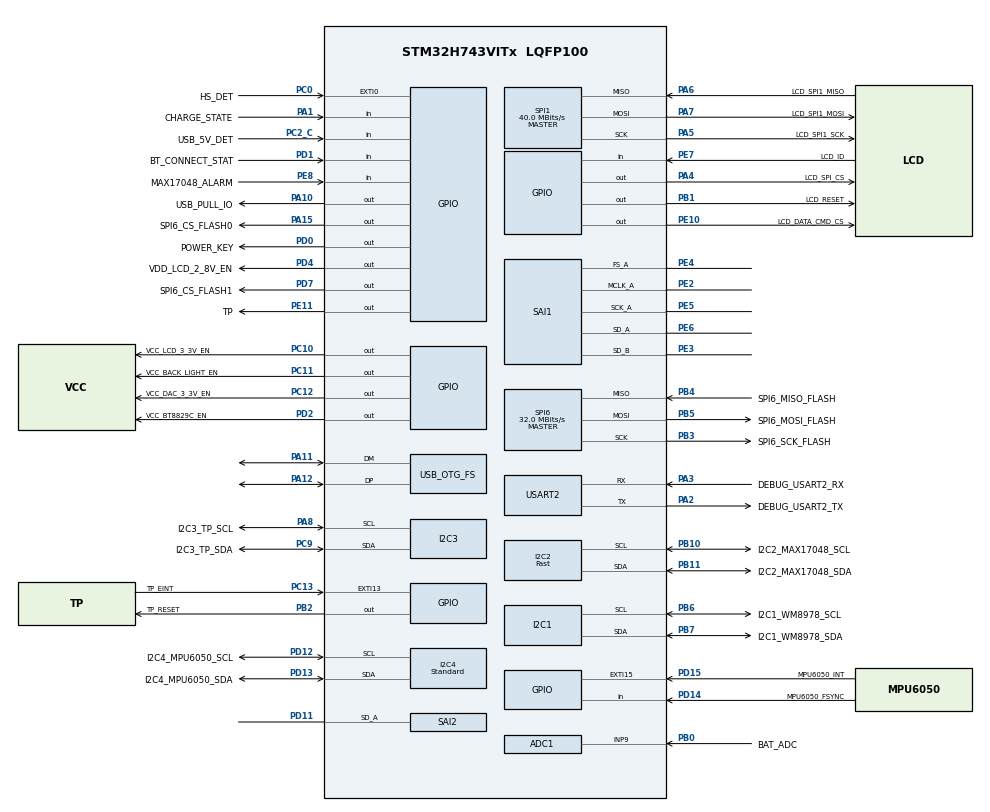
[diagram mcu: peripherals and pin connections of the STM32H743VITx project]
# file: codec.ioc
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ADC1.Channel-5\#ChannelRegularConversion=ADC_CHANNEL_9
ADC1.LowPowerAutoWait=ENABLE
ADC1.NbrOfConversionFlag=1
ADC1.OffsetNumber-5\#ChannelRegularConversion=ADC_OFFSET_NONE
ADC1.OffsetSignedSaturation-5\#ChannelRegularConversion=DISABLE
ADC1.Rank-5\#ChannelRegularConversion=1
ADC1.SamplingTime-5\#ChannelRegularConversion=ADC_SAMPLETIME_1CYCLE_5
ADC1.master=1
Bdma.I2C4_RX.0.Direction=DMA_PERIPH_TO_MEMORY
Bdma.I2C4_RX.0.EventEnable=DISABLE
Bdma.I2C4_RX.0.Instance=BDMA_Channel0
Bdma.I2C4_RX.0.MemDataAlignment=DMA_MDATAALIGN_BYTE
Bdma.I2C4_RX.0.MemInc=DMA_MINC_ENABLE
Bdma.I2C4_RX.0.Mode=DMA_NORMAL
Bdma.I2C4_RX.0.PeriphDataAlignment=DMA_PDATAALIGN_BYTE
Bdma.I2C4_RX.0.PeriphInc=DMA_PINC_DISABLE
Bdma.I2C4_RX.0.Polarity=HAL_DMAMUX_REQ_GEN_RISING
Bdma.I2C4_RX.0.Priority=DMA_PRIORITY_LOW
Bdma.I2C4_RX.0.RequestNumber=1
Bdma.I2C4_RX.0.SignalID=NONE
Bdma.I2C4_RX.0.SyncEnable=DISABLE
Bdma.I2C4_RX.0.SyncPolarity=HAL_DMAMUX_SYNC_NO_EVENT
Bdma.I2C4_RX.0.SyncRequestNumber=1
Bdma.I2C4_RX.0.SyncSignalID=NONE
Bdma.I2C4_TX.1.Direction=DMA_MEMORY_TO_PERIPH
Bdma.I2C4_TX.1.EventEnable=DISABLE
Bdma.I2C4_TX.1.Instance=BDMA_Channel1
Bdma.I2C4_TX.1.MemDataAlignment=DMA_MDATAALIGN_BYTE
Bdma.I2C4_TX.1.MemInc=DMA_MINC_ENABLE
Bdma.I2C4_TX.1.Mode=DMA_NORMAL
Bdma.I2C4_TX.1.PeriphDataAlignment=DMA_PDATAALIGN_BYTE
Bdma.I2C4_TX.1.PeriphInc=DMA_PINC_DISABLE
Bdma.I2C4_TX.1.Polarity=HAL_DMAMUX_REQ_GEN_RISING
Bdma.I2C4_TX.1.Priority=DMA_PRIORITY_LOW
Bdma.I2C4_TX.1.RequestNumber=1
Bdma.I2C4_TX.1.SignalID=NONE
Bdma.I2C4_TX.1.SyncEnable=DISABLE
Bdma.I2C4_TX.1.SyncPolarity=HAL_DMAMUX_SYNC_NO_EVENT
Bdma.I2C4_TX.1.SyncRequestNumber=1
Bdma.I2C4_TX.1.SyncSignalID=NONE
Bdma.Request0=I2C4_RX
Bdma.Request1=I2C4_TX
Bdma.Request2=SPI6_RX
Bdma.Request3=SPI6_TX
Bdma.RequestsNb=4
Bdma.SPI6_RX.2.Direction=DMA_PERIPH_TO_MEMORY
Bdma.SPI6_RX.2.EventEnable=DISABLE
Bdma.SPI6_RX.2.Instance=BDMA_Channel2
Bdma.SPI6_RX.2.MemDataAlignment=DMA_MDATAALIGN_BYTE
Bdma.SPI6_RX.2.MemInc=DMA_MINC_ENABLE
Bdma.SPI6_RX.2.Mode=DMA_NORMAL
Bdma.SPI6_RX.2.PeriphDataAlignment=DMA_PDATAALIGN_BYTE
Bdma.SPI6_RX.2.PeriphInc=DMA_PINC_DISABLE
Bdma.SPI6_RX.2.Polarity=HAL_DMAMUX_REQ_GEN_RISING
Bdma.SPI6_RX.2.Priority=DMA_PRIORITY_LOW
Bdma.SPI6_RX.2.RequestNumber=1
Bdma.SPI6_RX.2.SignalID=NONE
Bdma.SPI6_RX.2.SyncEnable=DISABLE
Bdma.SPI6_RX.2.SyncPolarity=HAL_DMAMUX_SYNC_NO_EVENT
Bdma.SPI6_RX.2.SyncRequestNumber=1
Bdma.SPI6_RX.2.SyncSignalID=NONE
Bdma.SPI6_TX.3.Direction=DMA_MEMORY_TO_PERIPH
Bdma.SPI6_TX.3.EventEnable=DISABLE
Bdma.SPI6_TX.3.Instance=BDMA_Channel3
Bdma.SPI6_TX.3.MemDataAlignment=DMA_MDATAALIGN_BYTE
Bdma.SPI6_TX.3.MemInc=DMA_MINC_ENABLE
Bdma.SPI6_TX.3.Mode=DMA_NORMAL
Bdma.SPI6_TX.3.PeriphDataAlignment=DMA_PDATAALIGN_BYTE
Bdma.SPI6_TX.3.PeriphInc=DMA_PINC_DISABLE
Bdma.SPI6_TX.3.Polarity=HAL_DMAMUX_REQ_GEN_RISING
Bdma.SPI6_TX.3.Priority=DMA_PRIORITY_LOW
Bdma.SPI6_TX.3.RequestNumber=1
Bdma.SPI6_TX.3.SignalID=NONE
Bdma.SPI6_TX.3.SyncEnable=DISABLE
Bdma.SPI6_TX.3.SyncPolarity=HAL_DMAMUX_SYNC_NO_EVENT
Bdma.SPI6_TX.3.SyncRequestNumber=1
Bdma.SPI6_TX.3.SyncSignalID=NONE
CORTEX_M7.AccessPermission-Cortex_Memory_Protection_Unit_Region0_Settings=MPU_REGION_FULL_ACCESS
CORTEX_M7.AccessPermission-Cortex_Memory_Protection_Unit_Region1_Settings=MPU_REGION_FULL_ACCESS
CORTEX_M7.AccessPermission-Cortex_Memory_Protection_Unit_Region2_Settings=MPU_REGION_FULL_ACCESS
CORTEX_M7.AccessPermission-Cortex_Memory_Protection_Unit_Region3_Settings=MPU_REGION_FULL_ACCESS
CORTEX_M7.BaseAddress-Cortex_Memory_Protection_Unit_Region0_Settings=0x24000000
CORTEX_M7.BaseAddress-Cortex_Memory_Protection_Unit_Region1_Settings=0x38000000
CORTEX_M7.BaseAddress-Cortex_Memory_Protection_Unit_Region2_Settings=0x30000000
CORTEX_M7.BaseAddress-Cortex_Memory_Protection_Unit_Region3_Settings=0x30020000
CORTEX_M7.CPU_DCache=Enabled
CORTEX_M7.CPU_ICache=Enabled
CORTEX_M7.Enable-Cortex_Memory_Protection_Unit_Region0_Settings=MPU_REGION_ENABLE
CORTEX_M7.Enable-Cortex_Memory_Protection_Unit_Region1_Settings=MPU_REGION_ENABLE
CORTEX_M7.Enable-Cortex_Memory_Protection_Unit_Region2_Settings=MPU_REGION_ENABLE
CORTEX_M7.Enable-Cortex_Memory_Protection_Unit_Region3_Settings=MPU_REGION_ENABLE
CORTEX_M7.IsBufferable-Cortex_Memory_Protection_Unit_Region0_Settings=MPU_ACCESS_BUFFERABLE
CORTEX_M7.IsCacheable-Cortex_Memory_Protection_Unit_Region0_Settings=MPU_ACCESS_CACHEABLE
CORTEX_M7.IsCacheable-Cortex_Memory_Protection_Unit_Region1_Settings=MPU_ACCESS_CACHEABLE
CORTEX_M7.IsCacheable-Cortex_Memory_Protection_Unit_Region2_Settings=MPU_ACCESS_CACHEABLE
CORTEX_M7.IsCacheable-Cortex_Memory_Protection_Unit_Region3_Settings=MPU_ACCESS_CACHEABLE
CORTEX_M7.IsShareable-Cortex_Memory_Protection_Unit_Region1_Settings=MPU_ACCESS_SHAREABLE
CORTEX_M7.IsShareable-Cortex_Memory_Protection_Unit_Region2_Settings=MPU_ACCESS_SHAREABLE
CORTEX_M7.IsShareable-Cortex_Memory_Protection_Unit_Region3_Settings=MPU_ACCESS_SHAREABLE
CORTEX_M7.MPU_Control=MPU_PRIVILEGED_DEFAULT
CORTEX_M7.Size-Cortex_Memory_Protection_Unit_Region0_Settings=MPU_REGION_SIZE_512KB
CORTEX_M7.Size-Cortex_Memory_Protection_Unit_Region1_Settings=MPU_REGION_SIZE_64KB
CORTEX_M7.Size-Cortex_Memory_Protection_Unit_Region2_Settings=MPU_REGION_SIZE_128KB
CORTEX_M7.Size-Cortex_Memory_Protection_Unit_Region3_Settings=MPU_REGION_SIZE_128KB
CORTEX_M7.TypeExtField-Cortex_Memory_Protection_Unit_Region0_Settings=MPU_TEX_LEVEL1
CORTEX_M7.TypeExtField-Cortex_Memory_Protection_Unit_Region1_Settings=MPU_TEX_LEVEL1
CORTEX_M7.TypeExtField-Cortex_Memory_Protection_Unit_Region2_Settings=MPU_TEX_LEVEL1
CORTEX_M7.TypeExtField-Cortex_Memory_Protection_Unit_Region3_Settings=MPU_TEX_LEVEL1
Dma.I2C1_RX.7.Direction=DMA_PERIPH_TO_MEMORY
Dma.I2C1_RX.7.EventEnable=DISABLE
Dma.I2C1_RX.7.FIFOMode=DMA_FIFOMODE_DISABLE
Dma.I2C1_RX.7.Instance=DMA2_Stream4
Dma.I2C1_RX.7.MemDataAlignment=DMA_MDATAALIGN_BYTE
Dma.I2C1_RX.7.MemInc=DMA_MINC_ENABLE
Dma.I2C1_RX.7.Mode=DMA_NORMAL
Dma.I2C1_RX.7.PeriphDataAlignment=DMA_PDATAALIGN_BYTE
Dma.I2C1_RX.7.PeriphInc=DMA_PINC_DISABLE
Dma.I2C1_RX.7.Polarity=HAL_DMAMUX_REQ_GEN_RISING
Dma.I2C1_RX.7.Priority=DMA_PRIORITY_LOW
Dma.I2C1_RX.7.RequestNumber=1
Dma.I2C1_RX.7.SignalID=NONE
Dma.I2C1_RX.7.SyncEnable=DISABLE
Dma.I2C1_RX.7.SyncPolarity=HAL_DMAMUX_SYNC_NO_EVENT
Dma.I2C1_RX.7.SyncRequestNumber=1
Dma.I2C1_RX.7.SyncSignalID=NONE
Dma.I2C1_TX.8.Direction=DMA_MEMORY_TO_PERIPH
Dma.I2C1_TX.8.EventEnable=DISABLE
Dma.I2C1_TX.8.FIFOMode=DMA_FIFOMODE_DISABLE
Dma.I2C1_TX.8.Instance=DMA2_Stream5
Dma.I2C1_TX.8.MemDataAlignment=DMA_MDATAALIGN_BYTE
Dma.I2C1_TX.8.MemInc=DMA_MINC_ENABLE
Dma.I2C1_TX.8.Mode=DMA_NORMAL
Dma.I2C1_TX.8.PeriphDataAlignment=DMA_PDATAALIGN_BYTE
Dma.I2C1_TX.8.PeriphInc=DMA_PINC_DISABLE
Dma.I2C1_TX.8.Polarity=HAL_DMAMUX_REQ_GEN_RISING
Dma.I2C1_TX.8.Priority=DMA_PRIORITY_LOW
Dma.I2C1_TX.8.RequestNumber=1
Dma.I2C1_TX.8.SignalID=NONE
Dma.I2C1_TX.8.SyncEnable=DISABLE
Dma.I2C1_TX.8.SyncPolarity=HAL_DMAMUX_SYNC_NO_EVENT
Dma.I2C1_TX.8.SyncRequestNumber=1
Dma.I2C1_TX.8.SyncSignalID=NONE
Dma.I2C2_RX.5.Direction=DMA_PERIPH_TO_MEMORY
Dma.I2C2_RX.5.EventEnable=DISABLE
Dma.I2C2_RX.5.FIFOMode=DMA_FIFOMODE_DISABLE
Dma.I2C2_RX.5.Instance=DMA2_Stream2
Dma.I2C2_RX.5.MemDataAlignment=DMA_MDATAALIGN_BYTE
Dma.I2C2_RX.5.MemInc=DMA_MINC_ENABLE
Dma.I2C2_RX.5.Mode=DMA_NORMAL
Dma.I2C2_RX.5.PeriphDataAlignment=DMA_PDATAALIGN_BYTE
Dma.I2C2_RX.5.PeriphInc=DMA_PINC_DISABLE
Dma.I2C2_RX.5.Polarity=HAL_DMAMUX_REQ_GEN_RISING
Dma.I2C2_RX.5.Priority=DMA_PRIORITY_LOW
Dma.I2C2_RX.5.RequestNumber=1
Dma.I2C2_RX.5.SignalID=NONE
Dma.I2C2_RX.5.SyncEnable=DISABLE
Dma.I2C2_RX.5.SyncPolarity=HAL_DMAMUX_SYNC_NO_EVENT
Dma.I2C2_RX.5.SyncRequestNumber=1
Dma.I2C2_RX.5.SyncSignalID=NONE
Dma.I2C2_TX.6.Direction=DMA_MEMORY_TO_PERIPH
Dma.I2C2_TX.6.EventEnable=DISABLE
Dma.I2C2_TX.6.FIFOMode=DMA_FIFOMODE_DISABLE
Dma.I2C2_TX.6.Instance=DMA2_Stream3
Dma.I2C2_TX.6.MemDataAlignment=DMA_MDATAALIGN_BYTE
Dma.I2C2_TX.6.MemInc=DMA_MINC_ENABLE
Dma.I2C2_TX.6.Mode=DMA_NORMAL
Dma.I2C2_TX.6.PeriphDataAlignment=DMA_PDATAALIGN_BYTE
Dma.I2C2_TX.6.PeriphInc=DMA_PINC_DISABLE
Dma.I2C2_TX.6.Polarity=HAL_DMAMUX_REQ_GEN_RISING
Dma.I2C2_TX.6.Priority=DMA_PRIORITY_LOW
Dma.I2C2_TX.6.RequestNumber=1
Dma.I2C2_TX.6.SignalID=NONE
Dma.I2C2_TX.6.SyncEnable=DISABLE
Dma.I2C2_TX.6.SyncPolarity=HAL_DMAMUX_SYNC_NO_EVENT
Dma.I2C2_TX.6.SyncRequestNumber=1
Dma.I2C2_TX.6.SyncSignalID=NONE
Dma.I2C3_RX.9.Direction=DMA_PERIPH_TO_MEMORY
Dma.I2C3_RX.9.EventEnable=DISABLE
Dma.I2C3_RX.9.FIFOMode=DMA_FIFOMODE_DISABLE
Dma.I2C3_RX.9.Instance=DMA2_Stream6
Dma.I2C3_RX.9.MemDataAlignment=DMA_MDATAALIGN_BYTE
Dma.I2C3_RX.9.MemInc=DMA_MINC_ENABLE
Dma.I2C3_RX.9.Mode=DMA_NORMAL
Dma.I2C3_RX.9.PeriphDataAlignment=DMA_PDATAALIGN_BYTE
Dma.I2C3_RX.9.PeriphInc=DMA_PINC_DISABLE
Dma.I2C3_RX.9.Polarity=HAL_DMAMUX_REQ_GEN_RISING
Dma.I2C3_RX.9.Priority=DMA_PRIORITY_LOW
Dma.I2C3_RX.9.RequestNumber=1
Dma.I2C3_RX.9.SignalID=NONE
Dma.I2C3_RX.9.SyncEnable=DISABLE
Dma.I2C3_RX.9.SyncPolarity=HAL_DMAMUX_SYNC_NO_EVENT
Dma.I2C3_RX.9.SyncRequestNumber=1
Dma.I2C3_RX.9.SyncSignalID=NONE
Dma.I2C3_TX.10.Direction=DMA_MEMORY_TO_PERIPH
Dma.I2C3_TX.10.EventEnable=DISABLE
Dma.I2C3_TX.10.FIFOMode=DMA_FIFOMODE_DISABLE
Dma.I2C3_TX.10.Instance=DMA2_Stream7
Dma.I2C3_TX.10.MemDataAlignment=DMA_MDATAALIGN_BYTE
Dma.I2C3_TX.10.MemInc=DMA_MINC_ENABLE
Dma.I2C3_TX.10.Mode=DMA_NORMAL
Dma.I2C3_TX.10.PeriphDataAlignment=DMA_PDATAALIGN_BYTE
Dma.I2C3_TX.10.PeriphInc=DMA_PINC_DISABLE
Dma.I2C3_TX.10.Polarity=HAL_DMAMUX_REQ_GEN_RISING
Dma.I2C3_TX.10.Priority=DMA_PRIORITY_LOW
Dma.I2C3_TX.10.RequestNumber=1
Dma.I2C3_TX.10.SignalID=NONE
Dma.I2C3_TX.10.SyncEnable=DISABLE
Dma.I2C3_TX.10.SyncPolarity=HAL_DMAMUX_SYNC_NO_EVENT
Dma.I2C3_TX.10.SyncRequestNumber=1
Dma.I2C3_TX.10.SyncSignalID=NONE
Dma.Request0=SAI1_A
Dma.Request1=SAI1_B
Dma.Request10=I2C3_TX
Dma.Request11=SPI1_TX
Dma.Request2=SAI2_A
Dma.Request3=USART2_RX
Dma.Request4=USART2_TX
Dma.Request5=I2C2_RX
Dma.Request6=I2C2_TX
Dma.Request7=I2C1_RX
Dma.Request8=I2C1_TX
Dma.Request9=I2C3_RX
Dma.SAI1_A.0.Direction=DMA_MEMORY_TO_PERIPH
Dma.SAI1_A.0.EventEnable=DISABLE
Dma.SAI1_A.0.FIFOMode=DMA_FIFOMODE_ENABLE
Dma.SAI1_A.0.FIFOThreshold=DMA_FIFO_THRESHOLD_FULL
Dma.SAI1_A.0.Instance=DMA1_Stream0
Dma.SAI1_A.0.MemBurst=DMA_MBURST_SINGLE
Dma.SAI1_A.0.MemDataAlignment=DMA_MDATAALIGN_WORD
Dma.SAI1_A.0.MemInc=DMA_MINC_ENABLE
Dma.SAI1_A.0.Mode=DMA_CIRCULAR
Dma.SAI1_A.0.PeriphBurst=DMA_PBURST_SINGLE
Dma.SAI1_A.0.PeriphDataAlignment=DMA_PDATAALIGN_WORD
Dma.SAI1_A.0.PeriphInc=DMA_PINC_DISABLE
Dma.SAI1_A.0.Polarity=HAL_DMAMUX_REQ_GEN_RISING
Dma.SAI1_A.0.Priority=DMA_PRIORITY_HIGH
Dma.SAI1_A.0.RequestNumber=1
Dma.SAI1_A.0.SignalID=NONE
Dma.SAI1_A.0.SyncEnable=DISABLE
Dma.SAI1_A.0.SyncPolarity=HAL_DMAMUX_SYNC_NO_EVENT
Dma.SAI1_A.0.SyncRequestNumber=1
Dma.SAI1_A.0.SyncSignalID=NONE
Dma.SAI1_B.1.Direction=DMA_PERIPH_TO_MEMORY
Dma.SAI1_B.1.EventEnable=DISABLE
Dma.SAI1_B.1.FIFOMode=DMA_FIFOMODE_ENABLE
Dma.SAI1_B.1.FIFOThreshold=DMA_FIFO_THRESHOLD_FULL
Dma.SAI1_B.1.Instance=DMA1_Stream2
Dma.SAI1_B.1.MemBurst=DMA_MBURST_SINGLE
Dma.SAI1_B.1.MemDataAlignment=DMA_MDATAALIGN_WORD
Dma.SAI1_B.1.MemInc=DMA_MINC_ENABLE
Dma.SAI1_B.1.Mode=DMA_CIRCULAR
Dma.SAI1_B.1.PeriphBurst=DMA_PBURST_SINGLE
Dma.SAI1_B.1.PeriphDataAlignment=DMA_PDATAALIGN_WORD
Dma.SAI1_B.1.PeriphInc=DMA_PINC_DISABLE
Dma.SAI1_B.1.Polarity=HAL_DMAMUX_REQ_GEN_RISING
Dma.SAI1_B.1.Priority=DMA_PRIORITY_HIGH
Dma.SAI1_B.1.RequestNumber=1
Dma.SAI1_B.1.SignalID=NONE
Dma.SAI1_B.1.SyncEnable=DISABLE
Dma.SAI1_B.1.SyncPolarity=HAL_DMAMUX_SYNC_NO_EVENT
Dma.SAI1_B.1.SyncRequestNumber=1
Dma.SAI1_B.1.SyncSignalID=NONE
Dma.SAI2_A.2.Direction=DMA_PERIPH_TO_MEMORY
Dma.SAI2_A.2.EventEnable=DISABLE
Dma.SAI2_A.2.FIFOMode=DMA_FIFOMODE_ENABLE
Dma.SAI2_A.2.FIFOThreshold=DMA_FIFO_THRESHOLD_FULL
Dma.SAI2_A.2.Instance=DMA1_Stream1
Dma.SAI2_A.2.MemBurst=DMA_MBURST_SINGLE
Dma.SAI2_A.2.MemDataAlignment=DMA_MDATAALIGN_WORD
Dma.SAI2_A.2.MemInc=DMA_MINC_ENABLE
Dma.SAI2_A.2.Mode=DMA_CIRCULAR
Dma.SAI2_A.2.PeriphBurst=DMA_PBURST_SINGLE
Dma.SAI2_A.2.PeriphDataAlignment=DMA_PDATAALIGN_WORD
Dma.SAI2_A.2.PeriphInc=DMA_PINC_DISABLE
Dma.SAI2_A.2.Polarity=HAL_DMAMUX_REQ_GEN_RISING
Dma.SAI2_A.2.Priority=DMA_PRIORITY_HIGH
Dma.SAI2_A.2.RequestNumber=1
Dma.SAI2_A.2.SignalID=NONE
Dma.SAI2_A.2.SyncEnable=DISABLE
Dma.SAI2_A.2.SyncPolarity=HAL_DMAMUX_SYNC_NO_EVENT
Dma.SAI2_A.2.SyncRequestNumber=1
Dma.SAI2_A.2.SyncSignalID=NONE
Dma.SPI1_TX.11.Direction=DMA_MEMORY_TO_PERIPH
Dma.SPI1_TX.11.EventEnable=DISABLE
Dma.SPI1_TX.11.FIFOMode=DMA_FIFOMODE_DISABLE
Dma.SPI1_TX.11.Instance=DMA1_Stream5
Dma.SPI1_TX.11.MemDataAlignment=DMA_MDATAALIGN_HALFWORD
Dma.SPI1_TX.11.MemInc=DMA_MINC_ENABLE
Dma.SPI1_TX.11.Mode=DMA_NORMAL
Dma.SPI1_TX.11.PeriphDataAlignment=DMA_PDATAALIGN_HALFWORD
Dma.SPI1_TX.11.PeriphInc=DMA_PINC_DISABLE
Dma.SPI1_TX.11.Polarity=HAL_DMAMUX_REQ_GEN_RISING
Dma.SPI1_TX.11.Priority=DMA_PRIORITY_LOW
Dma.SPI1_TX.11.RequestNumber=1
Dma.SPI1_TX.11.SignalID=NONE
Dma.SPI1_TX.11.SyncEnable=DISABLE
Dma.SPI1_TX.11.SyncPolarity=HAL_DMAMUX_SYNC_NO_EVENT
Dma.SPI1_TX.11.SyncRequestNumber=1
Dma.SPI1_TX.11.SyncSignalID=NONE
Dma.USART2_RX.3.Direction=DMA_PERIPH_TO_MEMORY
Dma.USART2_RX.3.EventEnable=DISABLE
Dma.USART2_RX.3.FIFOMode=DMA_FIFOMODE_DISABLE
Dma.USART2_RX.3.Instance=DMA1_Stream3
Dma.USART2_RX.3.MemDataAlignment=DMA_MDATAALIGN_BYTE
Dma.USART2_RX.3.MemInc=DMA_MINC_ENABLE
Dma.USART2_RX.3.Mode=DMA_NORMAL
Dma.USART2_RX.3.PeriphDataAlignment=DMA_PDATAALIGN_BYTE
Dma.USART2_RX.3.PeriphInc=DMA_PINC_DISABLE
Dma.USART2_RX.3.Polarity=HAL_DMAMUX_REQ_GEN_RISING
Dma.USART2_RX.3.Priority=DMA_PRIORITY_LOW
Dma.USART2_RX.3.RequestNumber=1
Dma.USART2_RX.3.SignalID=NONE
Dma.USART2_RX.3.SyncEnable=DISABLE
Dma.USART2_RX.3.SyncPolarity=HAL_DMAMUX_SYNC_NO_EVENT
Dma.USART2_RX.3.SyncRequestNumber=1
Dma.USART2_RX.3.SyncSignalID=NONE
Dma.USART2_TX.4.Direction=DMA_MEMORY_TO_PERIPH
Dma.USART2_TX.4.EventEnable=DISABLE
Dma.USART2_TX.4.FIFOMode=DMA_FIFOMODE_DISABLE
Dma.USART2_TX.4.Instance=DMA1_Stream4
Dma.USART2_TX.4.MemDataAlignment=DMA_MDATAALIGN_BYTE
Dma.USART2_TX.4.MemInc=DMA_MINC_ENABLE
Dma.USART2_TX.4.Mode=DMA_NORMAL
Dma.USART2_TX.4.PeriphDataAlignment=DMA_PDATAALIGN_BYTE
Dma.USART2_TX.4.PeriphInc=DMA_PINC_DISABLE
Dma.USART2_TX.4.Polarity=HAL_DMAMUX_REQ_GEN_RISING
Dma.USART2_TX.4.Priority=DMA_PRIORITY_LOW
Dma.USART2_TX.4.RequestNumber=1
Dma.USART2_TX.4.SignalID=NONE
Dma.USART2_TX.4.SyncEnable=DISABLE
Dma.USART2_TX.4.SyncPolarity=HAL_DMAMUX_SYNC_NO_EVENT
Dma.USART2_TX.4.SyncRequestNumber=1
Dma.USART2_TX.4.SyncSignalID=NONE
I2C1.CustomTiming=Disabled
I2C1.Timing=0x00C0EAFF
I2C2.CustomTiming=Enabled
I2C2.I2C_Speed_Mode=I2C_Fast
I2C2.Timing=0x00B03FDB
I2C3.CustomTiming=Enabled
I2C3.Speed=40
I2C3.Timing=0x00C0EAFF
I2C4.CustomTiming=Disabled
I2C4.I2C_Speed_Mode=I2C_Standard
I2C4.Timing=0x10C0ECFF
Mcu.Family=STM32H7
Mcu.Name=STM32H743VITx
Mcu.Package=LQFP100
NVIC.ADC_IRQn=true\:0\:0\:false\:false\:true\:true\:true\:true
NVIC.BDMA_Channel0_IRQn=true\:0\:0\:false\:false\:true\:false\:true\:true
NVIC.BDMA_Channel1_IRQn=true\:0\:0\:false\:false\:true\:false\:true\:true
NVIC.BDMA_Channel2_IRQn=true\:0\:0\:false\:false\:true\:false\:true\:true
NVIC.BDMA_Channel3_IRQn=true\:0\:0\:false\:false\:true\:false\:true\:true
NVIC.DMA1_Stream0_IRQn=true\:0\:0\:false\:false\:true\:false\:true\:true
NVIC.DMA1_Stream1_IRQn=true\:0\:0\:false\:false\:true\:false\:true\:true
NVIC.DMA1_Stream2_IRQn=true\:0\:0\:false\:false\:true\:false\:true\:true
NVIC.DMA1_Stream3_IRQn=true\:0\:0\:false\:false\:true\:false\:true\:true
NVIC.DMA1_Stream4_IRQn=true\:0\:0\:false\:false\:true\:false\:true\:true
NVIC.DMA1_Stream5_IRQn=true\:0\:0\:false\:false\:true\:false\:true\:true
NVIC.DMA2_Stream2_IRQn=true\:0\:0\:false\:false\:true\:false\:true\:true
NVIC.DMA2_Stream3_IRQn=true\:0\:0\:false\:false\:true\:false\:true\:true
NVIC.DMA2_Stream4_IRQn=true\:0\:0\:false\:false\:true\:false\:true\:true
NVIC.DMA2_Stream5_IRQn=true\:0\:0\:false\:false\:true\:false\:true\:true
NVIC.DMA2_Stream6_IRQn=true\:0\:0\:false\:false\:true\:false\:true\:true
NVIC.DMA2_Stream7_IRQn=true\:0\:0\:false\:false\:true\:false\:true\:true
NVIC.EXTI0_IRQn=true\:0\:0\:false\:false\:true\:true\:true\:true
NVIC.EXTI15_10_IRQn=true\:0\:0\:false\:false\:true\:true\:true\:true
NVIC.OTG_FS_IRQn=true\:0\:0\:false\:false\:true\:false\:true\:true
NVIC.PVD_AVD_IRQn=true\:0\:0\:false\:false\:true\:true\:true\:true
NVIC.PriorityGroup=NVIC_PRIORITYGROUP_4
NVIC.SPI1_IRQn=true\:0\:0\:false\:false\:true\:false\:true\:true
NVIC.SPI6_IRQn=true\:0\:0\:false\:false\:true\:false\:true\:true
NVIC.TIM3_IRQn=true\:0\:0\:false\:false\:true\:true\:true\:true
NVIC.TIM4_IRQn=true\:0\:0\:false\:false\:true\:true\:true\:true
NVIC.USART2_IRQn=true\:0\:0\:false\:false\:true\:true\:true\:true
PA1.GPIO_Label=CHARGE_STATE
PA1.Signal=GPIO_Input
PA10.GPIO_Label=USB_PULL_IO
PA10.PinState=GPIO_PIN_SET
PA10.Signal=GPIO_Output
PA11.Mode=Device_Only
PA11.Signal=USB_OTG_FS_DM
PA12.Mode=Device_Only
PA12.Signal=USB_OTG_FS_DP
PA13\ (JTMS/SWDIO).Mode=Serial_Wire
PA13\ (JTMS/SWDIO).Signal=DEBUG_JTMS-SWDIO
PA14\ (JTCK/SWCLK).Mode=Serial_Wire
PA14\ (JTCK/SWCLK).Signal=DEBUG_JTCK-SWCLK
PA15\ (JTDI).GPIO_Label=SPI6_CS_FLASH0
PA15\ (JTDI).GPIO_Speed=GPIO_SPEED_FREQ_MEDIUM
PA15\ (JTDI).PinState=GPIO_PIN_SET
PA15\ (JTDI).Signal=GPIO_Output
PA2.GPIO_Label=DEBUG_USART2_TX
PA2.Mode=Asynchronous
PA2.Signal=USART2_TX
PA3.GPIO_Label=DEBUG_USART2_RX
PA3.Mode=Asynchronous
PA3.Signal=USART2_RX
PA4.GPIO_Label=LCD_SPI_CS
PA4.Signal=GPIO_Output
PA5.GPIO_Label=LCD_SPI1_SCK
PA5.GPIO_Speed=GPIO_SPEED_FREQ_HIGH
PA5.Mode=Full_Duplex_Master
PA5.Signal=SPI1_SCK
PA6.GPIO_Label=LCD_SPI1_MISO
PA6.GPIO_Speed=GPIO_SPEED_FREQ_HIGH
PA6.Mode=Full_Duplex_Master
PA6.Signal=SPI1_MISO
PA7.GPIO_Label=LCD_SPI1_MOSI
PA7.GPIO_Speed=GPIO_SPEED_FREQ_HIGH
PA7.Mode=Full_Duplex_Master
PA7.Signal=SPI1_MOSI
PA8.GPIO_Label=I2C3_TP_SCL
PA8.GPIO_Pu=GPIO_PULLUP
PA8.Mode=I2C
PA8.Signal=I2C3_SCL
PB0.GPIO_Label=BAT_ADC
PB0.Signal=SharedAnalog_PB0
PB1.GPIO_Label=LCD_RESET
PB1.GPIO_ModeDefaultOutputPP=GPIO_MODE_OUTPUT_PP
PB1.GPIO_PuPd=GPIO_NOPULL
PB1.GPIO_Speed=GPIO_SPEED_FREQ_LOW
PB1.PinState=GPIO_PIN_RESET
PB1.Signal=GPIO_Output
PB10.GPIO_Label=I2C2_MAX17048_SCL
PB10.GPIO_Pu=GPIO_PULLUP
PB10.GPIO_PuPd=GPIO_PULLUP
PB10.Mode=I2C
PB10.Signal=I2C2_SCL
PB11.GPIO_Label=I2C2_MAX17048_SDA
PB11.GPIO_Pu=GPIO_PULLUP
PB11.GPIO_PuPd=GPIO_PULLUP
PB11.Mode=I2C
PB11.Signal=I2C2_SDA
PB2.GPIO_Label=TP_RESET
PB2.GPIO_ModeDefaultOutputPP=GPIO_MODE_OUTPUT_PP
PB2.Signal=GPIO_Output
PB3\ (JTDO/TRACESWO).GPIO_Label=SPI6_SCK_FLASH
PB3\ (JTDO/TRACESWO).Mode=Full_Duplex_Master
PB3\ (JTDO/TRACESWO).Signal=SPI6_SCK
PB4\ (NJTRST).GPIO_Label=SPI6_MISO_FLASH
PB4\ (NJTRST).Mode=Full_Duplex_Master
PB4\ (NJTRST).Signal=SPI6_MISO
PB5.GPIO_Label=SPI6_MOSI_FLASH
PB5.Mode=Full_Duplex_Master
PB5.Signal=SPI6_MOSI
PB6.GPIO_Label=I2C1_WM8978_SCL
PB6.GPIO_Pu=GPIO_PULLUP
PB6.GPIO_PuPd=GPIO_PULLUP
PB6.Mode=I2C
PB6.Signal=I2C1_SCL
PB7.GPIO_Label=I2C1_WM8978_SDA
PB7.GPIO_Pu=GPIO_PULLUP
PB7.GPIO_PuPd=GPIO_PULLUP
PB7.Mode=I2C
PB7.Signal=I2C1_SDA
PC0.GPIO_Label=HS_DET
PC0.GPIO_ModeDefaultEXTI=GPIO_MODE_IT_FALLING
PC0.GPIO_PuPd=GPIO_PULLUP
PC0.Signal=GPXTI0
PC10.GPIO_Label=VCC_LCD_3_3V_EN
PC10.PinState=GPIO_PIN_SET
PC10.Signal=GPIO_Output
PC11.GPIO_Label=VCC_BACK_LIGHT_EN
PC11.PinState=GPIO_PIN_RESET
PC11.Signal=GPIO_Output
PC12.GPIO_Label=VCC_DAC_3_3V_EN
PC12.PinState=GPIO_PIN_SET
PC12.Signal=GPIO_Output
PC13.GPIO_Label=TP_EINT
PC13.Signal=GPXTI13
PC14-OSC32_IN\ (OSC32_IN).Mode=LSE-External-Oscillator
PC14-OSC32_IN\ (OSC32_IN).Signal=RCC_OSC32_IN
PC15-OSC32_OUT\ (OSC32_OUT).Mode=LSE-External-Oscillator
PC15-OSC32_OUT\ (OSC32_OUT).Signal=RCC_OSC32_OUT
PC2_C.GPIO_Label=USB_5V_DET
PC2_C.Signal=GPIO_Input
PC9.GPIO_Label=I2C3_TP_SDA
PC9.GPIO_Pu=GPIO_PULLUP
PC9.Mode=I2C
PC9.Signal=I2C3_SDA
PD0.GPIO_Label=POWER_KEY
PD0.Signal=GPIO_Output
PD1.GPIO_Label=BT_CONNECT_STAT
PD1.Signal=GPIO_Input
PD11.Mode=SAI_A_SyncSlave
PD11.Signal=SAI2_SD_A
PD12.GPIO_Label=I2C4_MPU6050_SCL
PD12.GPIO_Pu=GPIO_PULLUP
PD12.GPIO_PuPd=GPIO_PULLUP
PD12.Mode=I2C
PD12.Signal=I2C4_SCL
PD13.GPIO_Label=I2C4_MPU6050_SDA
PD13.GPIO_Pu=GPIO_PULLUP
PD13.GPIO_PuPd=GPIO_PULLUP
PD13.Mode=I2C
PD13.Signal=I2C4_SDA
PD14.GPIO_Label=MPU6050_FSYNC
PD14.Signal=GPIO_Input
PD15.GPIO_Label=MPU6050_INT
PD15.GPIO_ModeDefaultEXTI=GPIO_MODE_IT_FALLING
PD15.GPIO_PuPd=GPIO_PULLUP
PD15.Signal=GPXTI15
PD2.GPIO_Label=VCC_BT8829C_EN
PD2.PinState=GPIO_PIN_SET
PD2.Signal=GPIO_Output
PD4.GPIO_Label=VDD_LCD_2_8V_EN
PD4.PinState=GPIO_PIN_SET
PD4.Signal=GPIO_Output
PD7.GPIO_Label=SPI6_CS_FLASH1
PD7.GPIO_Speed=GPIO_SPEED_FREQ_MEDIUM
PD7.PinState=GPIO_PIN_SET
PD7.Signal=GPIO_Output
PE10.GPIO_Label=LCD_DATA_CMD_CS
PE10.PinState=GPIO_PIN_SET
PE10.Signal=GPIO_Output
PE11.GPIO_Label=TP
PE11.GPIO_Speed=GPIO_SPEED_FREQ_VERY_HIGH
PE11.PinState=GPIO_PIN_RESET
PE11.Signal=GPIO_Output
PE2.Mode=SAI_A_MasterWithClock
PE2.Signal=SAI1_MCLK_A
PE3.Mode=SAI_B_SyncSlave
PE3.Signal=SAI1_SD_B
PE4.Mode=SAI_A_MasterWithClock
PE4.Signal=SAI1_FS_A
PE5.Mode=SAI_A_MasterWithClock
PE5.Signal=SAI1_SCK_A
PE6.Mode=SAI_A_MasterWithClock
PE6.Signal=SAI1_SD_A
PE7.GPIO_Label=LCD_ID
PE7.Signal=GPIO_Input
PE8.GPIO_Label=MAX17048_ALARM
PE8.Signal=GPIO_Input
PH0-OSC_IN\ (PH0).Mode=HSE-External-Oscillator
PH0-OSC_IN\ (PH0).Signal=RCC_OSC_IN
PH1-OSC_OUT\ (PH1).Mode=HSE-External-Oscillator
PH1-OSC_OUT\ (PH1).Signal=RCC_OSC_OUT
PWR.Mode=PWR_PVD_MODE_IT_RISING
PWR.PVDLevel=PWR_PVDLEVEL_6
ProjectManager.HeapSize=0xC000
ProjectManager.StackSize=0xA000
ProjectManager.TargetToolchain=MDK-ARM V5
RCC.ADCFreq_Value=2048000
RCC.APB1Freq_Value=50000000
RCC.APB2Freq_Value=100000000
RCC.APB3Freq_Value=100000000
RCC.APB4Freq_Value=100000000
RCC.CortexFreq_Value=400000000
RCC.D1PPRE=RCC_APB3_DIV2
RCC.D2PPRE1=RCC_APB1_DIV4
RCC.D2PPRE2=RCC_APB2_DIV2
RCC.D3PPRE=RCC_APB4_DIV2
RCC.DIVM1=2
RCC.DIVM2=25
RCC.DIVM3=25
RCC.DIVN1=64
RCC.DIVN2=256
RCC.DIVN3=246
RCC.DIVP2=125
RCC.DIVP3=3
RCC.DIVQ1=10
RCC.DIVQ2=4
RCC.HCLKFreq_Value=200000000
RCC.HPRE=RCC_HCLK_DIV2
RCC.HSE_VALUE=25000000
RCC.PLL1_VCI_Range-AdvancedSettings=RCC_PLL1VCIRANGE_0
RCC.PLL1_VCO_SEL-AdvancedSettings=RCC_PLL1VCOMEDIUM
RCC.PLL2FRACN=0
RCC.PLL3FRACN=0
RCC.PLLFRACN=0
RCC.PLLSourceVirtual=RCC_PLLSOURCE_HSE
RCC.RTCClockSelection=RCC_RTCCLKSOURCE_LSE
RCC.SAI1CLockSelection=RCC_SAI1CLKSOURCE_PLL3
RCC.SAI23CLockSelection=RCC_SAI23CLKSOURCE_PLL3
RCC.SAI4ACLockSelection=RCC_SAI4ACLKSOURCE_PLL3
RCC.SPI6CLockSelection=RCC_SPI6CLKSOURCE_PLL2
RCC.SYSCLKFreq_VALUE=400000000
RCC.SYSCLKSource=RCC_SYSCLKSOURCE_PLLCLK
RCC.USART234578CLockSelection=RCC_USART234578CLKSOURCE_PLL2
RCC.USBCLockSelection=RCC_USBCLKSOURCE_HSI48
RCC.USBFreq_Value=48000000
SAI1.AudioFrequency-SAI_A_MasterWithClock=SAI_AUDIO_FREQUENCY_32K
SAI1.AudioMode-SAI_A_MasterWithClock=SAI_MODEMASTER_TX
SAI1.AudioMode-SAI_B_SyncSlave=SAI_MODESLAVE_RX
SAI1.BasicDataSize-SAI_A_MasterWithClock=SAI_PROTOCOL_DATASIZE_24BIT
SAI1.BasicDataSize-SAI_B_SyncSlave=SAI_PROTOCOL_DATASIZE_24BIT
SAI1.ErrorAudioFreq-SAI_A_MasterWithClock=0.09 %
SAI1.InitProtocol-SAI_A_MasterWithClock=Enable
SAI1.InitProtocol-SAI_B_SyncSlave=Enable
SAI1.Instance-SAI_A_MasterWithClock=SAI$Index_Block_A
SAI1.Instance-SAI_B_SyncSlave=SAI$Index_Block_B
SAI1.MClockEnable=SAI_MASTERCLOCK_ENABLE
SAI1.OutputDrive-SAI_A_MasterWithClock=SAI_OUTPUTDRIVE_ENABLE
SAI1.OutputDrive-SAI_B_SyncSlave=SAI_OUTPUTDRIVE_ENABLE
SAI1.RealAudioFreq-SAI_A_MasterWithClock=32.031 KHz
SAI1.SynchroExt=SAI_SYNCEXT_OUTBLOCKA_ENABLE
SAI1.Synchro_A=SAI_ASYNCHRONOUS
SAI1.VirtualMode-SAI_A_MasterWithClock=VM_MASTER
SAI1.VirtualMode-SAI_B_SyncSlave=VM_SLAVE
SAI1.VirtualProtocol-SAI_A_BASIC=VM_BASIC_PROTOCOL
SAI1.VirtualProtocol-SAI_B_BASIC=VM_BASIC_PROTOCOL
SAI2.AudioMode-SAI_A_SyncSlave=SAI_MODESLAVE_RX
SAI2.BasicDataSize-SAI_A_SyncSlave=SAI_PROTOCOL_DATASIZE_24BIT
SAI2.InitProtocol-SAI_A_SyncSlave=Enable
SAI2.Instance-SAI_A_SyncSlave=SAI$Index_Block_A
SAI2.OutputDrive-SAI_A_SyncSlave=SAI_OUTPUTDRIVE_ENABLE
SAI2.Synchro_A=SAI_SYNCHRONOUS_EXT_SAI1
SAI2.VirtualMode-SAI_A_SyncSlave=VM_SLAVE
SAI2.VirtualProtocol-SAI_A_BASIC=VM_BASIC_PROTOCOL
SH.SharedAnalog_PB0.0=ADC1_INN5
SH.SharedAnalog_PB0.1=ADC1_INP9,IN9-Single-Ended
SPI1.BaudRatePrescaler=SPI_BAUDRATEPRESCALER_2
SPI1.CalculateBaudRate=40.0 MBits/s
SPI1.DataSize=SPI_DATASIZE_16BIT
SPI1.Direction=SPI_DIRECTION_2LINES
SPI1.Mode=SPI_MODE_MASTER
SPI1.VirtualType=VM_MASTER
SPI6.CLKPhase=SPI_PHASE_2EDGE
SPI6.CLKPolarity=SPI_POLARITY_HIGH
SPI6.CalculateBaudRate=32.0 MBits/s
SPI6.DataSize=SPI_DATASIZE_8BIT
SPI6.Direction=SPI_DIRECTION_2LINES
SPI6.Mode=SPI_MODE_MASTER
SPI6.NSSPolarity=SPI_NSS_POLARITY_LOW
SPI6.VirtualType=VM_MASTER
TIM3.AutoReloadPreload=TIM_AUTORELOAD_PRELOAD_ENABLE
TIM3.Period=1000-1
TIM3.Prescaler=100-1
TIM4.AutoReloadPreload=TIM_AUTORELOAD_PRELOAD_ENABLE
TIM4.Period=100-1
TIM4.Prescaler=100-1
USART2.VirtualMode-Asynchronous=VM_ASYNC
USB_DEVICE.APP_RX_DATA_SIZE-CDC_FS=512
USB_DEVICE.APP_TX_DATA_SIZE-CDC_FS=512
USB_DEVICE.CLASS_NAME_FS=CDC
USB_DEVICE.MANUFACTURER_STRING-CDC_FS=AidiSciTech
USB_DEVICE.PRODUCT_STRING_CDC_FS=AidiSciTech Virtual ComPort
USB_DEVICE.VirtualMode-CDC_FS=Cdc
USB_DEVICE.VirtualModeFS=Cdc_FS
USB_OTG_FS.VirtualMode=Device_Only
VP_PWR_V_PVD_IN.Mode=Mode_PVD_Int
VP_RTC_VS_RTC_Activate.Mode=RTC_Enabled
VP_SAI1_VP_$IpInstance_SAIA_SAI_BASIC.Mode=SAI_A_BASIC
VP_SAI1_VP_$IpInstance_SAIB_SAI_BASIC.Mode=SAI_B_BASIC
VP_SAI1_VP_$IpInstance_SYNCHRO_EXTERNAL.Mode=SynchroExternal
VP_SAI2_VP_$IpInstance_SAIA_SAI_BASIC.Mode=SAI_A_BASIC
VP_TIM3_VS_ClockSourceINT.Mode=Internal
VP_TIM4_VS_ClockSourceINT.Mode=Internal
VP_USB_DEVICE_VS_USB_DEVICE_CDC_FS.Mode=CDC_FS
board=custom

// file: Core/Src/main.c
/* USER CODE BEGIN Header */
/**
  ******************************************************************************
  * @file           : main.c
  * @brief          : Main program body
  ******************************************************************************
  * @attention
  *
  * <h2><center>&copy; Copyright (c) 2021 STMicroelectronics.
  * All rights reserved.</center></h2>
  *
  * This software component is licensed by ST under BSD 3-Clause license,
  * the "License"; You may not use this file except in compliance with the
  * License. You may obtain a copy of the License at:
  *                        opensource.org/licenses/BSD-3-Clause
  *
  ******************************************************************************
  */
/* USER CODE END Header */
#include "main.h"
#include "adc.h"
#include "bdma.h"
#include "dma.h"
#include "i2c.h"
#include "rtc.h"
#include "sai.h"
#include "spi.h"
#include "tim.h"
#include "usart.h"
#include "usb_device.h"
#include "gpio.h"

void SystemClock_Config(void);
void PeriphCommonClock_Config(void);
static void MPU_Config(void);

/* USER CODE BEGIN 0 */
void MPU_Config(void);
/* USER CODE END 0 */

int main(void)
{
  /* USER CODE BEGIN 1 */
#ifndef NO_BL_NO_DEBUG
  User_InterruptVectorTable_Move();
#endif
  /* USER CODE END 1 */

  /* MPU Configuration--------------------------------------------------------*/
  MPU_Config();

  /* Enable I-Cache---------------------------------------------------------*/
  SCB_EnableICache();

  /* Enable D-Cache---------------------------------------------------------*/
  SCB_EnableDCache();

  /* MCU Configuration--------------------------------------------------------*/

  /* Reset of all peripherals, Initializes the Flash interface and the Systick. */
  HAL_Init();

  /* Configure the system clock */
  SystemClock_Config();

/* Configure the peripherals common clocks */
  PeriphCommonClock_Config();

  /* Initialize all configured peripherals */
  MX_GPIO_Init();
  MX_BDMA_Init();
  MX_DMA_Init();
  MX_I2C2_Init();
  MX_SAI1_Init();
  MX_SAI2_Init();
  MX_I2C4_Init();
  MX_USART2_UART_Init();
  MX_USB_DEVICE_Init();
  MX_I2C1_Init();
  MX_ADC1_Init();
  MX_I2C3_Init();
  MX_SPI1_Init();
  MX_SPI6_Init();
  MX_TIM3_Init();
  MX_TIM4_Init();
  MX_RTC_Init();
  /* USER CODE BEGIN 2 */
  User_Main_Task_Init();
  /* USER CODE END 2 */

  /* Infinite loop */
  while (1)
  {

    /* USER CODE BEGIN 3 */
    User_Main_Task_Process_Loop();
  }
  /* USER CODE END 3 */
}

void SystemClock_Config(void)
{
  RCC_OscInitTypeDef RCC_OscInitStruct = {0};
  RCC_ClkInitTypeDef RCC_ClkInitStruct = {0};

  /** Supply configuration update enable
  */
  HAL_PWREx_ConfigSupply(PWR_LDO_SUPPLY);

  /** Configure the main internal regulator output voltage
  */
  __HAL_PWR_VOLTAGESCALING_CONFIG(PWR_REGULATOR_VOLTAGE_SCALE1);

  while(!__HAL_PWR_GET_FLAG(PWR_FLAG_VOSRDY)) {}

  /** Configure LSE Drive Capability
  */
  HAL_PWR_EnableBkUpAccess();
  __HAL_RCC_LSEDRIVE_CONFIG(RCC_LSEDRIVE_LOW);

  /** Macro to configure the PLL clock source
  */
  __HAL_RCC_PLL_PLLSOURCE_CONFIG(RCC_PLLSOURCE_HSE);

  /** Initializes the RCC Oscillators according to the specified parameters
  * in the RCC_OscInitTypeDef structure.
  */
  RCC_OscInitStruct.OscillatorType = RCC_OSCILLATORTYPE_HSI48|RCC_OSCILLATORTYPE_HSE
                              |RCC_OSCILLATORTYPE_LSE;
  RCC_OscInitStruct.HSEState = RCC_HSE_ON;
  RCC_OscInitStruct.LSEState = RCC_LSE_ON;
  RCC_OscInitStruct.HSI48State = RCC_HSI48_ON;
  RCC_OscInitStruct.PLL.PLLState = RCC_PLL_ON;
  RCC_OscInitStruct.PLL.PLLSource = RCC_PLLSOURCE_HSE;
  RCC_OscInitStruct.PLL.PLLM = 2;
  RCC_OscInitStruct.PLL.PLLN = 64;
  RCC_OscInitStruct.PLL.PLLP = 2;
  RCC_OscInitStruct.PLL.PLLQ = 10;
  RCC_OscInitStruct.PLL.PLLR = 2;
  RCC_OscInitStruct.PLL.PLLRGE = RCC_PLL1VCIRANGE_3;
  RCC_OscInitStruct.PLL.PLLVCOSEL = RCC_PLL1VCOWIDE;
  RCC_OscInitStruct.PLL.PLLFRACN = 0;
  if (HAL_RCC_OscConfig(&RCC_OscInitStruct) != HAL_OK)
  {
    Error_Handler();
  }

  /** Initializes the CPU, AHB and APB buses clocks
  */
  RCC_ClkInitStruct.ClockType = RCC_CLOCKTYPE_HCLK|RCC_CLOCKTYPE_SYSCLK
                              |RCC_CLOCKTYPE_PCLK1|RCC_CLOCKTYPE_PCLK2
                              |RCC_CLOCKTYPE_D3PCLK1|RCC_CLOCKTYPE_D1PCLK1;
  RCC_ClkInitStruct.SYSCLKSource = RCC_SYSCLKSOURCE_PLLCLK;
  RCC_ClkInitStruct.SYSCLKDivider = RCC_SYSCLK_DIV1;
  RCC_ClkInitStruct.AHBCLKDivider = RCC_HCLK_DIV2;
  RCC_ClkInitStruct.APB3CLKDivider = RCC_APB3_DIV2;
  RCC_ClkInitStruct.APB1CLKDivider = RCC_APB1_DIV4;
  RCC_ClkInitStruct.APB2CLKDivider = RCC_APB2_DIV2;
  RCC_ClkInitStruct.APB4CLKDivider = RCC_APB4_DIV2;

  if (HAL_RCC_ClockConfig(&RCC_ClkInitStruct, FLASH_LATENCY_2) != HAL_OK)
  {
    Error_Handler();
  }
}

void PeriphCommonClock_Config(void)
{
  RCC_PeriphCLKInitTypeDef PeriphClkInitStruct = {0};

  /** Initializes the peripherals clock
  */
  PeriphClkInitStruct.PeriphClockSelection = RCC_PERIPHCLK_SPI6|RCC_PERIPHCLK_SAI1
                              |RCC_PERIPHCLK_SAI2|RCC_PERIPHCLK_USART2;
  PeriphClkInitStruct.PLL2.PLL2M = 25;
  PeriphClkInitStruct.PLL2.PLL2N = 256;
  PeriphClkInitStruct.PLL2.PLL2P = 125;
  PeriphClkInitStruct.PLL2.PLL2Q = 4;
  PeriphClkInitStruct.PLL2.PLL2R = 2;
  PeriphClkInitStruct.PLL2.PLL2RGE = RCC_PLL2VCIRANGE_0;
  PeriphClkInitStruct.PLL2.PLL2VCOSEL = RCC_PLL2VCOWIDE;
  PeriphClkInitStruct.PLL2.PLL2FRACN = 0;
  PeriphClkInitStruct.PLL3.PLL3M = 25;
  PeriphClkInitStruct.PLL3.PLL3N = 246;
  PeriphClkInitStruct.PLL3.PLL3P = 3;
  PeriphClkInitStruct.PLL3.PLL3Q = 2;
  PeriphClkInitStruct.PLL3.PLL3R = 2;
  PeriphClkInitStruct.PLL3.PLL3RGE = RCC_PLL3VCIRANGE_0;
  PeriphClkInitStruct.PLL3.PLL3VCOSEL = RCC_PLL3VCOWIDE;
  PeriphClkInitStruct.PLL3.PLL3FRACN = 0;
  PeriphClkInitStruct.Sai1ClockSelection = RCC_SAI1CLKSOURCE_PLL3;
  PeriphClkInitStruct.Sai23ClockSelection = RCC_SAI23CLKSOURCE_PLL3;
  PeriphClkInitStruct.Usart234578ClockSelection = RCC_USART234578CLKSOURCE_PLL2;
  PeriphClkInitStruct.Spi6ClockSelection = RCC_SPI6CLKSOURCE_PLL2;
  if (HAL_RCCEx_PeriphCLKConfig(&PeriphClkInitStruct) != HAL_OK)
  {
    Error_Handler();
  }
}

/* MPU Configuration */

void MPU_Config(void)
{
  MPU_Region_InitTypeDef MPU_InitStruct = {0};

  /* Disables the MPU */
  HAL_MPU_Disable();

  /** Initializes and configures the Region and the memory to be protected
  */
  MPU_InitStruct.Enable = MPU_REGION_ENABLE;
  MPU_InitStruct.Number = MPU_REGION_NUMBER0;
  MPU_InitStruct.BaseAddress = 0x24000000;
  MPU_InitStruct.Size = MPU_REGION_SIZE_512KB;
  MPU_InitStruct.SubRegionDisable = 0x0;
  MPU_InitStruct.TypeExtField = MPU_TEX_LEVEL1;
  MPU_InitStruct.AccessPermission = MPU_REGION_FULL_ACCESS;
  MPU_InitStruct.DisableExec = MPU_INSTRUCTION_ACCESS_ENABLE;
  MPU_InitStruct.IsShareable = MPU_ACCESS_NOT_SHAREABLE;
  MPU_InitStruct.IsCacheable = MPU_ACCESS_CACHEABLE;
  MPU_InitStruct.IsBufferable = MPU_ACCESS_BUFFERABLE;

  HAL_MPU_ConfigRegion(&MPU_InitStruct);

  /** Initializes and configures the Region and the memory to be protected
  */
  MPU_InitStruct.Number = MPU_REGION_NUMBER1;
  MPU_InitStruct.BaseAddress = 0x38000000;
  MPU_InitStruct.Size = MPU_REGION_SIZE_64KB;
  MPU_InitStruct.IsShareable = MPU_ACCESS_SHAREABLE;
  MPU_InitStruct.IsBufferable = MPU_ACCESS_NOT_BUFFERABLE;

  HAL_MPU_ConfigRegion(&MPU_InitStruct);

  /** Initializes and configures the Region and the memory to be protected
  */
  MPU_InitStruct.Number = MPU_REGION_NUMBER2;
  MPU_InitStruct.BaseAddress = 0x30000000;
  MPU_InitStruct.Size = MPU_REGION_SIZE_128KB;

  HAL_MPU_ConfigRegion(&MPU_InitStruct);

  /** Initializes and configures the Region and the memory to be protected
  */
  MPU_InitStruct.Number = MPU_REGION_NUMBER3;
  MPU_InitStruct.BaseAddress = 0x30020000;

  HAL_MPU_ConfigRegion(&MPU_InitStruct);
  /* Enables the MPU */
  HAL_MPU_Enable(MPU_PRIVILEGED_DEFAULT);

}

void Error_Handler(void)
{
  __disable_irq();
  while (1)
  {
  }
}

#ifdef  USE_FULL_ASSERT
/**
  * @brief  Reports the name of the source file and the source line number
  *         where the assert_param error has occurred.
  * @param  file: pointer to the source file name
  * @param  line: assert_param error line source number
  * @retval None
  */
void assert_failed(uint8_t *file, uint32_t line)
{
  /* USER CODE BEGIN 6 */
  /* User can add his own implementation to report the file name and line number,
     ex: printf("Wrong parameters value: file %s on line %d\r\n", file, line) */
  cm_backtrace_port_assert();
  /* USER CODE END 6 */
}
#endif /* USE_FULL_ASSERT */
